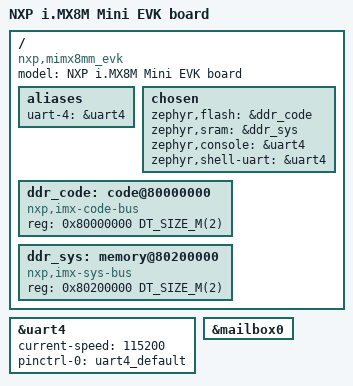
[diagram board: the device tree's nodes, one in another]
/*
 * Copyright (c) 2020, Manivannan Sadhasivam <mani@kernel.org>
 * Copyright (c) 2026 Testo SE & Co. KGaA
 *
 * SPDX-License-Identifier: Apache-2.0
 */

/dts-v1/;

#include <nxp/imx/nxp_imx8mm_m4.dtsi>

#include "imx8mm_evk-pinctrl.dtsi"

/ {
	compatible = "nxp,mimx8mm_evk";
	model = "NXP i.MX8M Mini EVK board";

	aliases {
		uart-4 = &uart4;
	};

	chosen {
		/* DDR */
		zephyr,flash = &ddr_code;
		zephyr,sram = &ddr_sys;
		zephyr,console = &uart4;
		zephyr,shell-uart = &uart4;
	};

	ddr_code: code@80000000 {
		compatible = "nxp,imx-code-bus";
		reg = <0x80000000 DT_SIZE_M(2)>;
		device_type = "memory";
	};

	ddr_sys: memory@80200000 {
		compatible = "nxp,imx-sys-bus";
		reg = <0x80200000 DT_SIZE_M(2)>;
		device_type = "memory";
	};
};

&uart4 {
	current-speed = <115200>;
	pinctrl-0 = <&uart4_default>;
	pinctrl-names = "default";
	status = "okay";
};

&mailbox0 {
	status = "okay";
};
